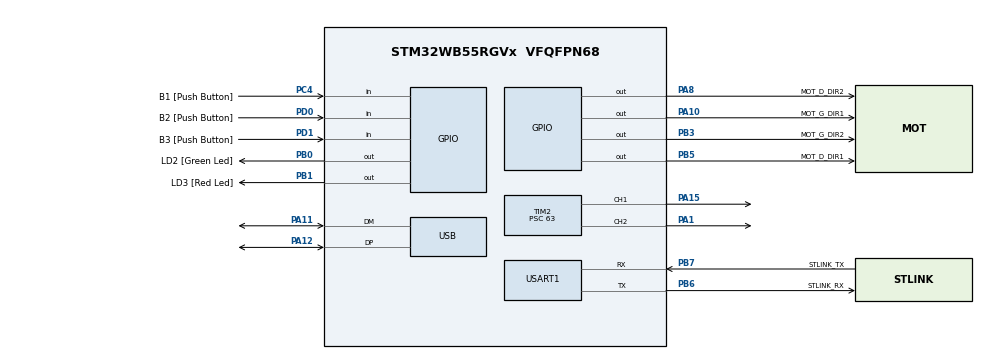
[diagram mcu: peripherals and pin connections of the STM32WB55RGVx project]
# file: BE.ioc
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Mcu.Family=STM32WB
Mcu.Name=STM32WB55RGVx
Mcu.Package=VFQFPN68
NVIC.PriorityGroup=NVIC_PRIORITYGROUP_4
OSC_IN.Mode=HSE-External-Oscillator
OSC_IN.Signal=RCC_OSC_IN
OSC_OUT.Mode=HSE-External-Oscillator
OSC_OUT.Signal=RCC_OSC_OUT
PA1.Signal=S_TIM2_CH2
PA10.GPIO_Label=MOT_G_DIR1
PA10.GPIO_Speed=GPIO_SPEED_FREQ_MEDIUM
PA10.Signal=GPIO_Output
PA11.Mode=Device
PA11.Signal=USB_DM
PA12.Mode=Device
PA12.Signal=USB_DP
PA13.GPIO_Label=JTMS
PA13.Mode=Serial_Wire
PA13.Signal=SYS_JTMS-SWDIO
PA14.GPIO_Label=JTCK
PA14.Mode=Serial_Wire
PA14.Signal=SYS_JTCK-SWCLK
PA15.Signal=S_TIM2_CH1
PA8.GPIO_Label=MOT_D_DIR2
PA8.GPIO_Speed=GPIO_SPEED_FREQ_MEDIUM
PA8.Signal=GPIO_Output
PB0.GPIO_Label=LD2 [Green Led]
PB0.Signal=GPIO_Output
PB1.GPIO_Label=LD3 [Red Led]
PB1.Signal=GPIO_Output
PB3.GPIO_Label=MOT_G_DIR2
PB3.GPIO_Speed=GPIO_SPEED_FREQ_MEDIUM
PB3.Signal=GPIO_Output
PB5.GPIO_Label=MOT_D_DIR1
PB5.GPIO_Speed=GPIO_SPEED_FREQ_MEDIUM
PB5.Signal=GPIO_Output
PB6.GPIO_Label=STLINK_RX
PB6.GPIO_PuPd=GPIO_PULLUP
PB6.Mode=Asynchronous
PB6.Signal=USART1_TX
PB7.GPIO_Label=STLINK_TX
PB7.GPIO_PuPd=GPIO_PULLUP
PB7.Mode=Asynchronous
PB7.Signal=USART1_RX
PC13.Mode=SYS_WakeUp1
PC13.Signal=SYS_WKUP2
PC14-OSC32_IN.Mode=LSE-External-Oscillator
PC14-OSC32_IN.Signal=RCC_OSC32_IN
PC15-OSC32_OUT.Mode=LSE-External-Oscillator
PC15-OSC32_OUT.Signal=RCC_OSC32_OUT
PC4.GPIO_Label=B1 [Push Button]
PC4.Signal=GPIO_Input
PD0.GPIO_Label=B2 [Push Button]
PD0.Signal=GPIO_Input
PD1.GPIO_Label=B3 [Push Button]
PD1.Signal=GPIO_Input
ProjectManager.HeapSize=0x200
ProjectManager.StackSize=0x400
ProjectManager.TargetToolchain=STM32CubeIDE
RCC.ADCFreq_Value=48000000
RCC.AHB2CLKDivider=RCC_SYSCLK_DIV2
RCC.AHBFreq_Value=64000000
RCC.APB1Freq_Value=64000000
RCC.APB1TimFreq_Value=64000000
RCC.APB2Freq_Value=64000000
RCC.APB2TimFreq_Value=64000000
RCC.APB3Freq_Value=16000000
RCC.Cortex2_Div=SYSTICK_CLKSOURCE_HCLK_DIV8
RCC.CortexFreq_Value=64000000
RCC.HCLKFreq_Value=64000000
RCC.HSE_VALUE=32000000
RCC.HSI48_VALUE=48000000
RCC.HSI_VALUE=16000000
RCC.LSE_Drive_Capability=RCC_LSEDRIVE_LOW
RCC.PLLN=32
RCC.PLLSAI1N=24
RCC.SMPSCLockSelectionVirtual=RCC_SMPSCLKSOURCE_HSI
RCC.SMPSCLockSelectionVirtualVirtual=RCC_SMPSCLKSOURCE_HSI
RCC.SMPSDivider=1
RCC.SYSCLKFreq_VALUE=64000000
RCC.SYSCLKSource=RCC_SYSCLKSOURCE_PLLCLK
RCC.USBFreq_Value=48000000
RCC.VCOOutputFreq_Value=128000000
SH.S_TIM2_CH1.0=TIM2_CH1,PWM Generation1 CH1
SH.S_TIM2_CH2.0=TIM2_CH2,PWM Generation2 CH2
TIM2.AutoReloadPreload=TIM_AUTORELOAD_PRELOAD_ENABLE
TIM2.Channel-PWM\ Generation1\ CH1=TIM_CHANNEL_1
TIM2.Channel-PWM\ Generation2\ CH2=TIM_CHANNEL_2
TIM2.Period=999
TIM2.Prescaler=63
USART1.VirtualMode-Asynchronous=VM_ASYNC
USART1.WordLength=WORDLENGTH_7B
VP_MEMORYMAP_VS_MEMORYMAP.Mode=CurAppReg
VP_TIM2_VS_ClockSourceINT.Mode=Internal
board=P-NUCLEO-WB55-NUCLEO

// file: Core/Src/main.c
/* USER CODE BEGIN Header */
/**
  ******************************************************************************
  * @file           : main.c
  * @brief          : Main program body
  ******************************************************************************
  * @attention
  *
  * Copyright (c) 2026 STMicroelectronics.
  * All rights reserved.
  *
  * This software is licensed under terms that can be found in the LICENSE file
  * in the root directory of this software component.
  * If no LICENSE file comes with this software, it is provided AS-IS.
  *
  ******************************************************************************
  */
/* USER CODE END Header */
#include "main.h"
#include "memorymap.h"
#include "tim.h"
#include "usart.h"
#include "usb.h"
#include "gpio.h"

void SystemClock_Config(void);
void PeriphCommonClock_Config(void);

int main(void)
{

  /* MCU Configuration--------------------------------------------------------*/

  /* Reset of all peripherals, Initializes the Flash interface and the Systick. */
  HAL_Init();

  /* Configure the system clock */
  SystemClock_Config();

/* Configure the peripherals common clocks */
  PeriphCommonClock_Config();

  /* Initialize all configured peripherals */
  MX_GPIO_Init();
  MX_USART1_UART_Init();
  MX_USB_PCD_Init();
  MX_TIM2_Init();
  /* USER CODE BEGIN 2 */
  // Démarrer les signaux PWM
  HAL_TIM_PWM_Start(&htim2, TIM_CHANNEL_1);
  HAL_TIM_PWM_Start(&htim2, TIM_CHANNEL_2);

  // Définir la direction (Avancer)
  // Moteur Gauche
  // HAL_GPIO_WritePin(GPIOA, GPIO_PIN_10, GPIO_PIN_SET);
  // HAL_GPIO_WritePin(GPIOB, GPIO_PIN_3, GPIO_PIN_RESET);
  // Moteur Droit
  HAL_GPIO_WritePin(GPIOB, GPIO_PIN_5, GPIO_PIN_SET);
  HAL_GPIO_WritePin(GPIOA, GPIO_PIN_8, GPIO_PIN_RESET);

  // Appliquer la vitesse (50% de 1000)
  __HAL_TIM_SET_COMPARE(&htim2, TIM_CHANNEL_1, 500);
  __HAL_TIM_SET_COMPARE(&htim2, TIM_CHANNEL_2, 500);

  HAL_Delay(2000); // Avance pendant 2 secondes

  // 4. Stop
  __HAL_TIM_SET_COMPARE(&htim2, TIM_CHANNEL_1, 0);
  __HAL_TIM_SET_COMPARE(&htim2, TIM_CHANNEL_2, 0);
  /* USER CODE END 2 */

  /* Infinite loop */
  while (1)
  {

  }
}

void SystemClock_Config(void)
{
  RCC_OscInitTypeDef RCC_OscInitStruct = {0};
  RCC_ClkInitTypeDef RCC_ClkInitStruct = {0};

  /** Configure LSE Drive Capability
  */
  HAL_PWR_EnableBkUpAccess();
  __HAL_RCC_LSEDRIVE_CONFIG(RCC_LSEDRIVE_LOW);

  /** Configure the main internal regulator output voltage
  */
  __HAL_PWR_VOLTAGESCALING_CONFIG(PWR_REGULATOR_VOLTAGE_SCALE1);

  /** Initializes the RCC Oscillators according to the specified parameters
  * in the RCC_OscInitTypeDef structure.
  */
  RCC_OscInitStruct.OscillatorType = RCC_OSCILLATORTYPE_HSI|RCC_OSCILLATORTYPE_HSE
                              |RCC_OSCILLATORTYPE_LSE|RCC_OSCILLATORTYPE_MSI;
  RCC_OscInitStruct.HSEState = RCC_HSE_ON;
  RCC_OscInitStruct.LSEState = RCC_LSE_ON;
  RCC_OscInitStruct.HSIState = RCC_HSI_ON;
  RCC_OscInitStruct.MSIState = RCC_MSI_ON;
  RCC_OscInitStruct.HSICalibrationValue = RCC_HSICALIBRATION_DEFAULT;
  RCC_OscInitStruct.MSICalibrationValue = RCC_MSICALIBRATION_DEFAULT;
  RCC_OscInitStruct.MSIClockRange = RCC_MSIRANGE_6;
  RCC_OscInitStruct.PLL.PLLState = RCC_PLL_ON;
  RCC_OscInitStruct.PLL.PLLSource = RCC_PLLSOURCE_MSI;
  RCC_OscInitStruct.PLL.PLLM = RCC_PLLM_DIV1;
  RCC_OscInitStruct.PLL.PLLN = 32;
  RCC_OscInitStruct.PLL.PLLP = RCC_PLLP_DIV2;
  RCC_OscInitStruct.PLL.PLLR = RCC_PLLR_DIV2;
  RCC_OscInitStruct.PLL.PLLQ = RCC_PLLQ_DIV2;
  if (HAL_RCC_OscConfig(&RCC_OscInitStruct) != HAL_OK)
  {
    Error_Handler();
  }

  /** Configure the SYSCLKSource, HCLK, PCLK1 and PCLK2 clocks dividers
  */
  RCC_ClkInitStruct.ClockType = RCC_CLOCKTYPE_HCLK4|RCC_CLOCKTYPE_HCLK2
                              |RCC_CLOCKTYPE_HCLK|RCC_CLOCKTYPE_SYSCLK
                              |RCC_CLOCKTYPE_PCLK1|RCC_CLOCKTYPE_PCLK2;
  RCC_ClkInitStruct.SYSCLKSource = RCC_SYSCLKSOURCE_PLLCLK;
  RCC_ClkInitStruct.AHBCLKDivider = RCC_SYSCLK_DIV1;
  RCC_ClkInitStruct.APB1CLKDivider = RCC_HCLK_DIV1;
  RCC_ClkInitStruct.APB2CLKDivider = RCC_HCLK_DIV1;
  RCC_ClkInitStruct.AHBCLK2Divider = RCC_SYSCLK_DIV2;
  RCC_ClkInitStruct.AHBCLK4Divider = RCC_SYSCLK_DIV1;

  if (HAL_RCC_ClockConfig(&RCC_ClkInitStruct, FLASH_LATENCY_3) != HAL_OK)
  {
    Error_Handler();
  }

  /** Enable MSI Auto calibration
  */
  HAL_RCCEx_EnableMSIPLLMode();
}

void PeriphCommonClock_Config(void)
{
  RCC_PeriphCLKInitTypeDef PeriphClkInitStruct = {0};

  /** Initializes the peripherals clock
  */
  PeriphClkInitStruct.PeriphClockSelection = RCC_PERIPHCLK_SMPS;
  PeriphClkInitStruct.SmpsClockSelection = RCC_SMPSCLKSOURCE_HSI;
  PeriphClkInitStruct.SmpsDivSelection = RCC_SMPSCLKDIV_RANGE0;

  if (HAL_RCCEx_PeriphCLKConfig(&PeriphClkInitStruct) != HAL_OK)
  {
    Error_Handler();
  }
}

void Error_Handler(void)
{
  __disable_irq();
  while (1)
  {
  }
}
